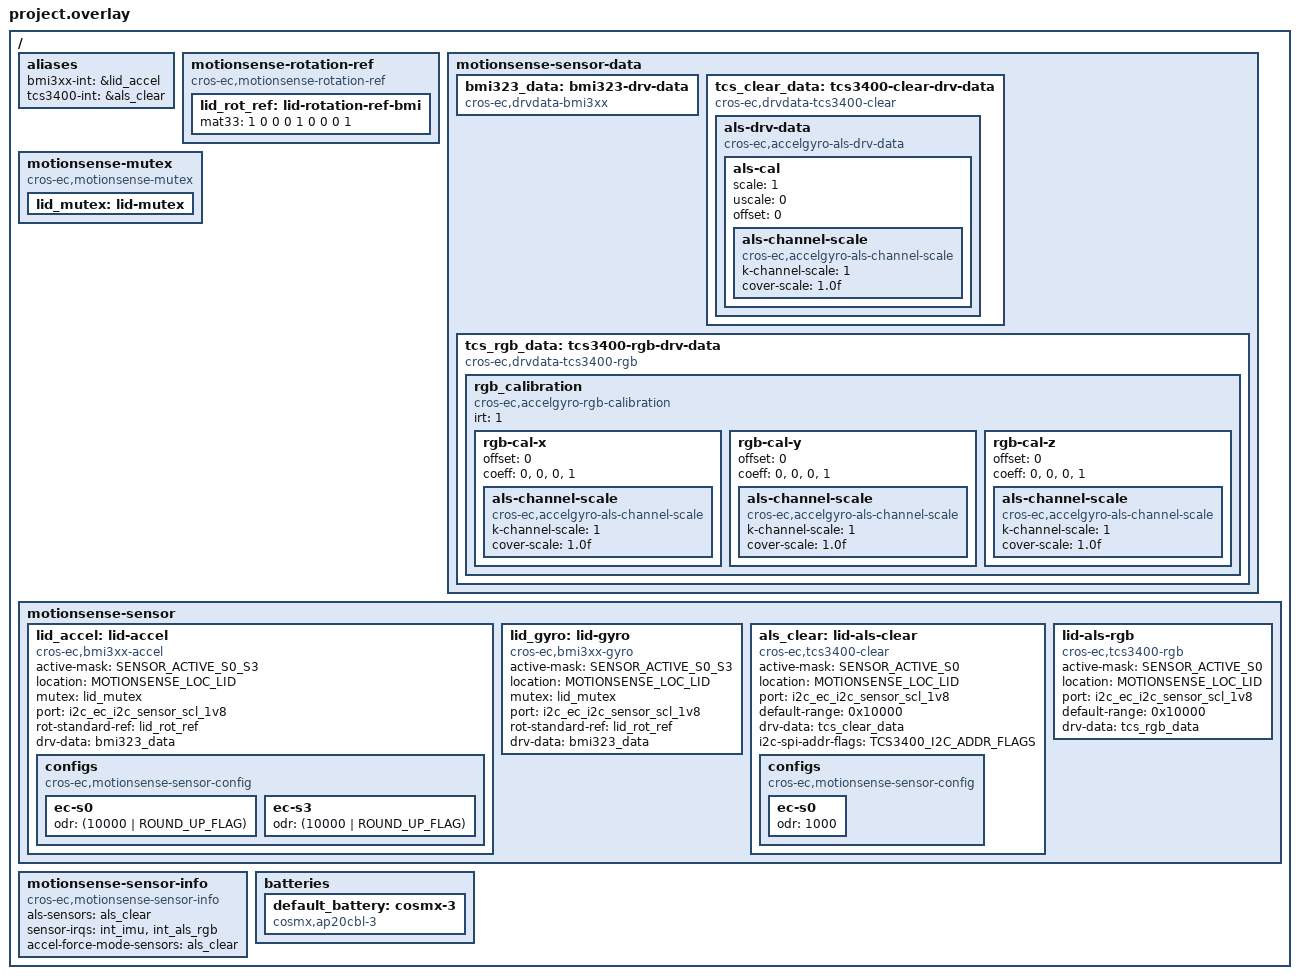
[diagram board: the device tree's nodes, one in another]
#include <cros/cbi_flash.dtsi>
#include <dt-bindings/motionsense/utils.h>

#include "../arbitrage.dtsi"
#include "../common.dtsi"
#include "../pdc.dtsi"
#include "../generated.dtsi"
#include "../interrupts.dtsi"
#include "../keyboard.dtsi"
#include "../overlay.dtsi"
#include "../power_signal.dtsi"

/ {
	aliases {
		bmi3xx-int = &lid_accel;
		tcs3400-int = &als_clear;
	};

	/* Rotation matrix used by drivers. */
	motionsense-rotation-ref {
		compatible = "cros-ec,motionsense-rotation-ref";
		lid_rot_ref: lid-rotation-ref-bmi {
			mat33 = <1 0 0
				 0 1 0
				 0 0 1>;
		};
	};

	motionsense-sensor-data {
		bmi323_data: bmi323-drv-data {
			compatible = "cros-ec,drvdata-bmi3xx";
			status = "okay";
		};

		tcs_clear_data: tcs3400-clear-drv-data {
			compatible = "cros-ec,drvdata-tcs3400-clear";
			status = "okay";

			als-drv-data {
				compatible = "cros-ec,accelgyro-als-drv-data";
				als-cal {
					scale = <1>;
					uscale = <0>;
					offset = <0>;
					als-channel-scale {
					compatible =
					"cros-ec,accelgyro-als-channel-scale";
						k-channel-scale = <1>;
						cover-scale = "1.0f";
					};
				};
			};
		};

		tcs_rgb_data: tcs3400-rgb-drv-data {
			compatible = "cros-ec,drvdata-tcs3400-rgb";
			status = "okay";

			/* node for rgb_calibration_t defined in accelgyro.h */
			rgb_calibration {
				compatible =
					"cros-ec,accelgyro-rgb-calibration";

				irt = <1>;

				rgb-cal-x {
					offset = <0>;
					coeff = "0", "0", "0", "1";
					als-channel-scale {
					compatible =
					"cros-ec,accelgyro-als-channel-scale";
						k-channel-scale = <1>;
						cover-scale = "1.0f";
					};
				};
				rgb-cal-y {
					offset = <0>;
					coeff = "0", "0", "0", "1";
					als-channel-scale {
					compatible =
					"cros-ec,accelgyro-als-channel-scale";
						k-channel-scale = <1>;
						cover-scale = "1.0f";
					};
				};
				rgb-cal-z {
					offset = <0>;
					coeff = "0", "0", "0", "1";
					als-channel-scale {
					compatible =
					"cros-ec,accelgyro-als-channel-scale";
						k-channel-scale = <1>;
						cover-scale = "1.0f";
					};
				};
			};
		};
	};
	/*
	 * Declare mutexes used by sensor drivers.
	 * A mutex node is used to create an instance of mutex_t.
	 * A mutex node is referenced by a sensor node if the
	 * corresponding sensor driver needs to use the
	 * instance of the mutex.
	 */
	motionsense-mutex {
		compatible = "cros-ec,motionsense-mutex";
		lid_mutex: lid-mutex {
		};
	};

	motionsense-sensor {
		lid_accel: lid-accel {
			compatible = "cros-ec,bmi3xx-accel";
			status = "okay";

			active-mask = "SENSOR_ACTIVE_S0_S3";
			location = "MOTIONSENSE_LOC_LID";
			mutex = <&lid_mutex>;
			port = <&i2c_ec_i2c_sensor_scl_1v8>;
			rot-standard-ref = <&lid_rot_ref>;
			drv-data = <&bmi323_data>;
			configs {
				compatible =
					"cros-ec,motionsense-sensor-config";
				ec-s0 {
					odr = <(10000 | ROUND_UP_FLAG)>;
				};
				ec-s3 {
					odr = <(10000 | ROUND_UP_FLAG)>;
				};
			};
		};

		lid_gyro: lid-gyro {
			compatible = "cros-ec,bmi3xx-gyro";
			status = "okay";

			active-mask = "SENSOR_ACTIVE_S0_S3";
			location = "MOTIONSENSE_LOC_LID";
			mutex = <&lid_mutex>;
			port = <&i2c_ec_i2c_sensor_scl_1v8>;
			rot-standard-ref = <&lid_rot_ref>;
			drv-data = <&bmi323_data>;
		};

		als_clear: lid-als-clear {
			compatible = "cros-ec,tcs3400-clear";
			status = "okay";

			active-mask = "SENSOR_ACTIVE_S0";
			location = "MOTIONSENSE_LOC_LID";
			port = <&i2c_ec_i2c_sensor_scl_1v8>;
			default-range = <0x10000>;
			drv-data = <&tcs_clear_data>;
			i2c-spi-addr-flags = "TCS3400_I2C_ADDR_FLAGS";
			configs {
				compatible =
					"cros-ec,motionsense-sensor-config";
				ec-s0 {
					/* Run ALS sensor in S0 */
					odr = <1000>;
				};
			};
		};

		lid-als-rgb {
			compatible = "cros-ec,tcs3400-rgb";
			status = "okay";

			active-mask = "SENSOR_ACTIVE_S0";
			location = "MOTIONSENSE_LOC_LID";
			port = <&i2c_ec_i2c_sensor_scl_1v8>;
			default-range = <0x10000>; /* scale = 1x, uscale = 0 */
			drv-data = <&tcs_rgb_data>;
		};
	};

	motionsense-sensor-info {
		compatible = "cros-ec,motionsense-sensor-info";

		/* list of entries for motion_als_sensors */
		als-sensors = <&als_clear>;
		/*
		 * list of GPIO interrupts that have to
		 * be enabled at initial stage
		 */
		sensor-irqs = <&int_imu &int_als_rgb>;
		/* list of sensors in force mode */
		accel-force-mode-sensors = <&als_clear>;
	};

	batteries {
		default_battery: cosmx-3 {
			compatible = "cosmx,ap20cbl-3", "battery-smart";
		};
	};
};
